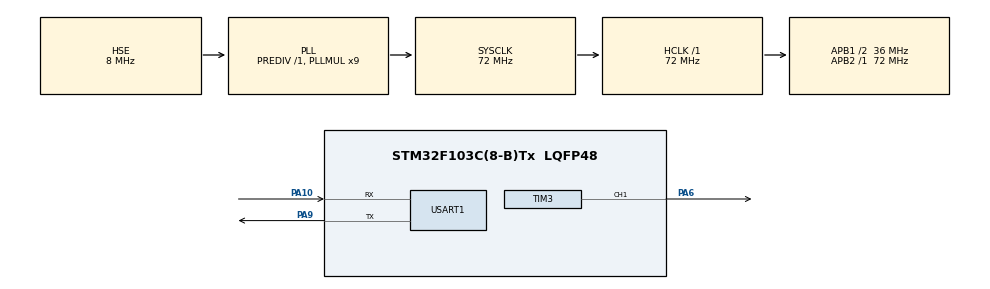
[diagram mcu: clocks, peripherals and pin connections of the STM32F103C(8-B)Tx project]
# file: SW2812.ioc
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Dma.Request0=USART1_RX
Dma.Request1=USART1_TX
Dma.Request2=TIM3_CH1/TRIG
Dma.TIM3_CH1/TRIG.2.Direction=DMA_MEMORY_TO_PERIPH
Dma.TIM3_CH1/TRIG.2.Instance=DMA1_Channel6
Dma.TIM3_CH1/TRIG.2.MemDataAlignment=DMA_MDATAALIGN_HALFWORD
Dma.TIM3_CH1/TRIG.2.MemInc=DMA_MINC_ENABLE
Dma.TIM3_CH1/TRIG.2.Mode=DMA_NORMAL
Dma.TIM3_CH1/TRIG.2.PeriphDataAlignment=DMA_PDATAALIGN_HALFWORD
Dma.TIM3_CH1/TRIG.2.PeriphInc=DMA_PINC_DISABLE
Dma.TIM3_CH1/TRIG.2.Priority=DMA_PRIORITY_LOW
Dma.USART1_RX.0.Direction=DMA_PERIPH_TO_MEMORY
Dma.USART1_RX.0.Instance=DMA1_Channel5
Dma.USART1_RX.0.MemDataAlignment=DMA_MDATAALIGN_BYTE
Dma.USART1_RX.0.MemInc=DMA_MINC_ENABLE
Dma.USART1_RX.0.Mode=DMA_NORMAL
Dma.USART1_RX.0.PeriphDataAlignment=DMA_PDATAALIGN_BYTE
Dma.USART1_RX.0.PeriphInc=DMA_PINC_DISABLE
Dma.USART1_RX.0.Priority=DMA_PRIORITY_LOW
Dma.USART1_TX.1.Direction=DMA_MEMORY_TO_PERIPH
Dma.USART1_TX.1.Instance=DMA1_Channel4
Dma.USART1_TX.1.MemDataAlignment=DMA_MDATAALIGN_BYTE
Dma.USART1_TX.1.MemInc=DMA_MINC_ENABLE
Dma.USART1_TX.1.Mode=DMA_NORMAL
Dma.USART1_TX.1.PeriphDataAlignment=DMA_PDATAALIGN_BYTE
Dma.USART1_TX.1.PeriphInc=DMA_PINC_DISABLE
Dma.USART1_TX.1.Priority=DMA_PRIORITY_LOW
Mcu.Family=STM32F1
Mcu.Name=STM32F103C(8-B)Tx
Mcu.Package=LQFP48
NVIC.DMA1_Channel4_IRQn=true\:0\:0\:false\:false\:true
NVIC.DMA1_Channel5_IRQn=true\:0\:0\:false\:false\:true
NVIC.DMA1_Channel6_IRQn=true\:0\:0\:false\:false\:true
NVIC.PriorityGroup=NVIC_PRIORITYGROUP_4
NVIC.TIM3_IRQn=true\:0\:0\:false\:false\:true
NVIC.TIM4_IRQn=true\:0\:0\:false\:false\:true
NVIC.USART1_IRQn=true\:0\:0\:false\:false\:true
PA10.Mode=Asynchronous
PA10.Signal=USART1_RX
PA13.Mode=Trace_Asynchronous_SW
PA13.Signal=SYS_JTMS-SWDIO
PA14.Mode=Trace_Asynchronous_SW
PA14.Signal=SYS_JTCK-SWCLK
PA6.Signal=S_TIM3_CH1
PA9.Mode=Asynchronous
PA9.Signal=USART1_TX
PB3.Mode=Trace_Asynchronous_SW
PB3.Signal=SYS_JTDO-TRACESWO
PD0-OSC_IN.Mode=HSE-External-Oscillator
PD0-OSC_IN.Signal=RCC_OSC_IN
PD1-OSC_OUT.Mode=HSE-External-Oscillator
PD1-OSC_OUT.Signal=RCC_OSC_OUT
ProjectManager.HeapSize=0x200
ProjectManager.StackSize=0x400
ProjectManager.TargetToolchain=MDK-ARM V5
RCC.AHBFreq_Value=72000000
RCC.APB1CLKDivider=RCC_HCLK_DIV2
RCC.APB1Freq_Value=36000000
RCC.APB1TimFreq_Value=72000000
RCC.APB2Freq_Value=72000000
RCC.APB2TimFreq_Value=72000000
RCC.HCLKFreq_Value=72000000
RCC.PLLMUL=RCC_PLL_MUL9
RCC.PLLSourceVirtual=RCC_PLLSOURCE_HSE
RCC.SYSCLKFreq_VALUE=72000000
RCC.SYSCLKSource=RCC_SYSCLKSOURCE_PLLCLK
RCC.USBFreq_Value=72000000
SH.S_TIM3_CH1.0=TIM3_CH1,PWM Generation1 CH1
TIM3.Channel-PWM\ Generation1\ CH1=TIM_CHANNEL_1
TIM3.Period=90-1
TIM3.TIM_MasterOutputTrigger=TIM_TRGO_UPDATE
TIM4.Period=1000-1
TIM4.Prescaler=72-1
USART1.VirtualMode=VM_ASYNC
VP_TIM3_VS_ClockSourceINT.Mode=Internal
VP_TIM4_VS_ClockSourceINT.Mode=Internal
board=SW2812

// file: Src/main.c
/**
  ******************************************************************************
  * File Name          : main.c
  * Description        : Main program body
  ******************************************************************************
  *
  * COPYRIGHT(c) 2018 STMicroelectronics
  *
  * Redistribution and use in source and binary forms, with or without modification,
  * are permitted provided that the following conditions are met:
  *   1. Redistributions of source code must retain the above copyright notice,
  *      this list of conditions and the following disclaimer.
  *   2. Redistributions in binary form must reproduce the above copyright notice,
  *      this list of conditions and the following disclaimer in the documentation
  *      and/or other materials provided with the distribution.
  *   3. Neither the name of STMicroelectronics nor the names of its contributors
  *      may be used to endorse or promote products derived from this software
  *      without specific prior written permission.
  *
  * THIS SOFTWARE IS PROVIDED BY THE COPYRIGHT HOLDERS AND CONTRIBUTORS "AS IS"
  * AND ANY EXPRESS OR IMPLIED WARRANTIES, INCLUDING, BUT NOT LIMITED TO, THE
  * IMPLIED WARRANTIES OF MERCHANTABILITY AND FITNESS FOR A PARTICULAR PURPOSE ARE
  * DISCLAIMED. IN NO EVENT SHALL THE COPYRIGHT HOLDER OR CONTRIBUTORS BE LIABLE
  * FOR ANY DIRECT, INDIRECT, INCIDENTAL, SPECIAL, EXEMPLARY, OR CONSEQUENTIAL
  * DAMAGES (INCLUDING, BUT NOT LIMITED TO, PROCUREMENT OF SUBSTITUTE GOODS OR
  * SERVICES; LOSS OF USE, DATA, OR PROFITS; OR BUSINESS INTERRUPTION) HOWEVER
  * CAUSED AND ON ANY THEORY OF LIABILITY, WHETHER IN CONTRACT, STRICT LIABILITY,
  * OR TORT (INCLUDING NEGLIGENCE OR OTHERWISE) ARISING IN ANY WAY OUT OF THE USE
  * OF THIS SOFTWARE, EVEN IF ADVISED OF THE POSSIBILITY OF SUCH DAMAGE.
  *
  ******************************************************************************
  */
#include "main.h"
#include "stm32f1xx_hal.h"
#include "dma.h"
#include "tim.h"
#include "usart.h"
#include "gpio.h"

/* USER CODE BEGIN Includes */
#include "SystemState.h"
#include "WS2812.h"
/* USER CODE END Includes */

/* USER CODE BEGIN PV */
/* Private variables ---------------------------------------------------------*/
float Time_pre=0;
/* USER CODE END PV */

void SystemClock_Config(void);
void Error_Handler(void);

/* USER CODE BEGIN PFP */
int UART_Inite(void);
/* Private function prototypes -----------------------------------------------*/

/* USER CODE END PFP */

int main(void)
{

  /* MCU Configuration----------------------------------------------------------*/

  /* Reset of all peripherals, Initializes the Flash interface and the Systick. */
  HAL_Init();

  /* Configure the system clock */
  SystemClock_Config();

  /* Initialize all configured peripherals */
  MX_GPIO_Init();
  MX_DMA_Init();
  MX_USART1_UART_Init();
  MX_TIM3_Init();
  MX_TIM4_Init();

  /* USER CODE BEGIN 2 */
	SystemState_Inite();
	UART_Inite();
	LED_5050DriverInite();
	LED_Data_Fill_All(50,50,50);
	printf("LED_Start\r\n");
  /* USER CODE END 2 */

  /* Infinite loop */
  while (1)
  {

  /* USER CODE BEGIN 3 */
		HAL_Delay(50);
		LED_Flash();

		LED_5050SentStar();//发送更新
  }
  /* USER CODE END 3 */

}

/** System Clock Configuration
*/
void SystemClock_Config(void)
{

  RCC_OscInitTypeDef RCC_OscInitStruct;
  RCC_ClkInitTypeDef RCC_ClkInitStruct;

    /**Initializes the CPU, AHB and APB busses clocks
    */
  RCC_OscInitStruct.OscillatorType = RCC_OSCILLATORTYPE_HSE;
  RCC_OscInitStruct.HSEState = RCC_HSE_ON;
  RCC_OscInitStruct.HSEPredivValue = RCC_HSE_PREDIV_DIV1;
  RCC_OscInitStruct.HSIState = RCC_HSI_ON;
  RCC_OscInitStruct.PLL.PLLState = RCC_PLL_ON;
  RCC_OscInitStruct.PLL.PLLSource = RCC_PLLSOURCE_HSE;
  RCC_OscInitStruct.PLL.PLLMUL = RCC_PLL_MUL9;
  if (HAL_RCC_OscConfig(&RCC_OscInitStruct) != HAL_OK)
  {
    Error_Handler();
  }

    /**Initializes the CPU, AHB and APB busses clocks
    */
  RCC_ClkInitStruct.ClockType = RCC_CLOCKTYPE_HCLK|RCC_CLOCKTYPE_SYSCLK
                              |RCC_CLOCKTYPE_PCLK1|RCC_CLOCKTYPE_PCLK2;
  RCC_ClkInitStruct.SYSCLKSource = RCC_SYSCLKSOURCE_PLLCLK;
  RCC_ClkInitStruct.AHBCLKDivider = RCC_SYSCLK_DIV1;
  RCC_ClkInitStruct.APB1CLKDivider = RCC_HCLK_DIV2;
  RCC_ClkInitStruct.APB2CLKDivider = RCC_HCLK_DIV1;

  if (HAL_RCC_ClockConfig(&RCC_ClkInitStruct, FLASH_LATENCY_2) != HAL_OK)
  {
    Error_Handler();
  }

    /**Configure the Systick interrupt time
    */
  HAL_SYSTICK_Config(HAL_RCC_GetHCLKFreq()/1000);

    /**Configure the Systick
    */
  HAL_SYSTICK_CLKSourceConfig(SYSTICK_CLKSOURCE_HCLK);

  /* SysTick_IRQn interrupt configuration */
  HAL_NVIC_SetPriority(SysTick_IRQn, 0, 0);
}

void Error_Handler(void)
{
  while(1)
  {
  }
}

/************************ (C) COPYRIGHT STMicroelectronics *****END OF FILE****/
